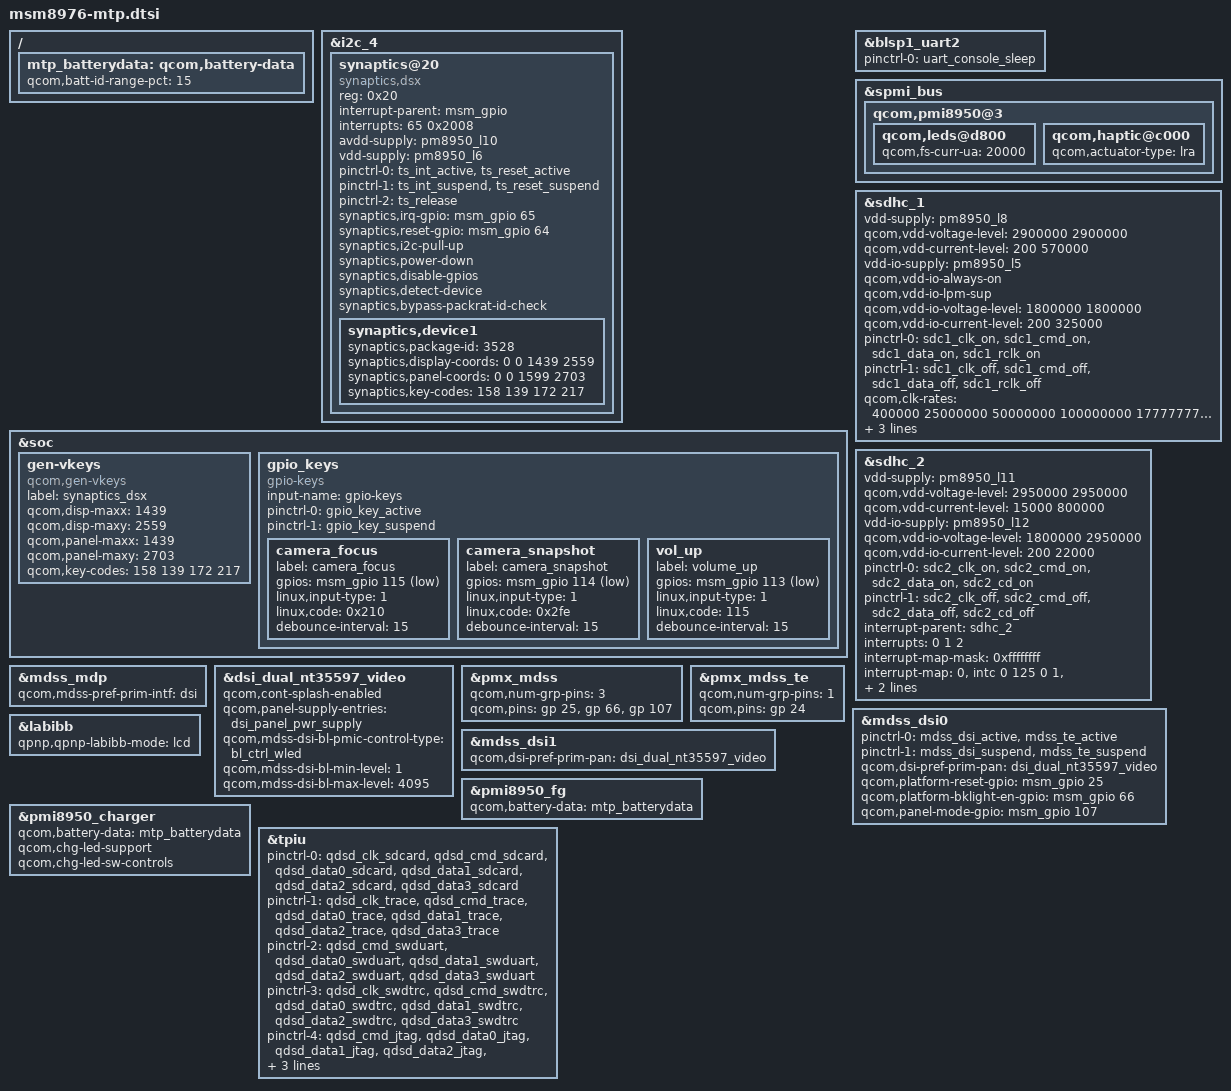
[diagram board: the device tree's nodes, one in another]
/*
 * Copyright (c) 2015, The Linux Foundation. All rights reserved.
 *
 * This program is free software; you can redistribute it and/or modify
 * it under the terms of the GNU General Public License version 2 and
 * only version 2 as published by the Free Software Foundation.
 *
 * This program is distributed in the hope that it will be useful,
 * but WITHOUT ANY WARRANTY; without even the implied warranty of
 * MERCHANTABILITY or FITNESS FOR A PARTICULAR PURPOSE.  See the
 * GNU General Public License for more details.
 */

#include "msm8976.dtsi"
#include "msm8976-pinctrl.dtsi"
#include "msm8976-camera-sensor-mtp.dtsi"

&i2c_4 { /* BLSP1 QUP4 */
	synaptics@20 {
		compatible = "synaptics,dsx";
		reg = <0x20>;
		interrupt-parent = <&msm_gpio>;
		interrupts = <65 0x2008>;
		avdd-supply = <&pm8950_l10>;
		vdd-supply = <&pm8950_l6>;
		/* pins used by touchscreen */
		pinctrl-names = "pmx_ts_active","pmx_ts_suspend","pmx_ts_release";
		pinctrl-0 = <&ts_int_active &ts_reset_active>;
		pinctrl-1 = <&ts_int_suspend &ts_reset_suspend>;
		pinctrl-2 = <&ts_release>;
		synaptics,irq-gpio = <&msm_gpio 65 0x2008>;
		synaptics,reset-gpio = <&msm_gpio 64 0x0>;
		synaptics,i2c-pull-up;
		synaptics,power-down;
		synaptics,disable-gpios;
		synaptics,detect-device;
		synaptics,bypass-packrat-id-check;
		synaptics,device1 {
			synaptics,package-id = <3528>;
			synaptics,display-coords = <0 0 1439 2559>;
			synaptics,panel-coords = <0 0 1599 2703>;
			synaptics,key-codes = <158 139 172 217>;
		};
	};
};

&soc {
	gen-vkeys {
		compatible = "qcom,gen-vkeys";
		label = "synaptics_dsx";
		qcom,disp-maxx = <1439>;
		qcom,disp-maxy = <2559>;
		qcom,panel-maxx = <1439>;
		qcom,panel-maxy = <2703>;
		qcom,key-codes = <158 139 172 217>;
	};

	gpio_keys {
		compatible = "gpio-keys";
		input-name = "gpio-keys";
		pinctrl-names = "tlmm_gpio_key_active","tlmm_gpio_key_suspend";
		pinctrl-0 = <&gpio_key_active>;
		pinctrl-1 = <&gpio_key_suspend>;

		camera_focus {
			label = "camera_focus";
			gpios = <&msm_gpio 115 0x1>;
			linux,input-type = <1>;
			linux,code = <0x210>;
			debounce-interval = <15>;
		};

		camera_snapshot {
			label = "camera_snapshot";
			gpios = <&msm_gpio 114 0x1>;
			linux,input-type = <1>;
			linux,code = <0x2fe>;
			debounce-interval = <15>;
		};

		vol_up {
			label = "volume_up";
			gpios = <&msm_gpio 113 0x1>;
			linux,input-type = <1>;
			linux,code = <115>;
			debounce-interval = <15>;
		};
	};
};

&blsp1_uart2 {
	status = "ok";
	pinctrl-names = "default";
	pinctrl-0 = <&uart_console_sleep>;
};


&spmi_bus {
	qcom,pmi8950@3 {
		qcom,leds@d800 {
			qcom,fs-curr-ua = <20000>;
		};

		qcom,haptic@c000 {
			qcom,actuator-type = "lra";
		};
	};
};

&sdhc_1 {
	vdd-supply = <&pm8950_l8>;
	qcom,vdd-voltage-level = <2900000 2900000>;
	qcom,vdd-current-level = <200 570000>;

	vdd-io-supply = <&pm8950_l5>;
	qcom,vdd-io-always-on;
	qcom,vdd-io-lpm-sup;
	qcom,vdd-io-voltage-level = <1800000 1800000>;
	qcom,vdd-io-current-level = <200 325000>;

	pinctrl-names = "active", "sleep";
	pinctrl-0 = <&sdc1_clk_on &sdc1_cmd_on &sdc1_data_on &sdc1_rclk_on>;
	pinctrl-1 = <&sdc1_clk_off &sdc1_cmd_off &sdc1_data_off &sdc1_rclk_off>;

	qcom,clk-rates = <400000 25000000 50000000 100000000 177777778 400000000>;
	qcom,bus-speed-mode = "HS400_1p8v", "HS200_1p8v", "DDR_1p8v";

	qcom,nonremovable;

	status = "ok";
};

&sdhc_2 {
	vdd-supply = <&pm8950_l11>;
	qcom,vdd-voltage-level = <2950000 2950000>;
	qcom,vdd-current-level = <15000 800000>;

	vdd-io-supply = <&pm8950_l12>;
	qcom,vdd-io-voltage-level = <1800000 2950000>;
	qcom,vdd-io-current-level = <200 22000>;

	pinctrl-names = "active", "sleep";
	pinctrl-0 = <&sdc2_clk_on &sdc2_cmd_on &sdc2_data_on &sdc2_cd_on>;
	pinctrl-1 = <&sdc2_clk_off &sdc2_cmd_off &sdc2_data_off &sdc2_cd_off>;

	#address-cells = <0>;
	interrupt-parent = <&sdhc_2>;
	interrupts = <0 1 2>;
	#interrupt-cells = <1>;
	interrupt-map-mask = <0xffffffff>;
	interrupt-map = <0 &intc 0 125 0
			1 &intc 0 221 0
			2 &msm_gpio 100 0>;
	interrupt-names = "hc_irq", "pwr_irq", "status_irq";
	cd-gpios = <&msm_gpio 100 0x1>;

	status = "ok";
};

&mdss_mdp {
	qcom,mdss-pref-prim-intf = "dsi";
};

&dsi_dual_nt35597_video {
	qcom,cont-splash-enabled;
	qcom,panel-supply-entries = <&dsi_panel_pwr_supply>;
	qcom,mdss-dsi-bl-pmic-control-type = "bl_ctrl_wled";
	qcom,mdss-dsi-bl-min-level = <1>;
	qcom,mdss-dsi-bl-max-level = <4095>;
};

&pmx_mdss {
	qcom,num-grp-pins = <3>;
	qcom,pins = <&gp 25>, <&gp 66>, <&gp 107>;
};

&pmx_mdss_te {
	qcom,num-grp-pins = <1>;
	qcom,pins = <&gp 24>;
};

&mdss_dsi0 {
	pinctrl-names = "mdss_default", "mdss_sleep";
	pinctrl-0 = <&mdss_dsi_active &mdss_te_active>;
	pinctrl-1 = <&mdss_dsi_suspend &mdss_te_suspend>;
	qcom,dsi-pref-prim-pan = <&dsi_dual_nt35597_video>;

	qcom,platform-reset-gpio = <&msm_gpio 25 0>;
	qcom,platform-bklight-en-gpio = <&msm_gpio 66 0>;
	qcom,panel-mode-gpio = <&msm_gpio 107 0>;
};

&mdss_dsi1 {
	qcom,dsi-pref-prim-pan = <&dsi_dual_nt35597_video>;
};

&labibb {
	status = "ok";
	qpnp,qpnp-labibb-mode = "lcd";
};

/{
	mtp_batterydata: qcom,battery-data {
		qcom,batt-id-range-pct = <15>;
		#include "batterydata-itech-3000mah-4200mv.dtsi"
		#include "batterydata-itech-3000mah.dtsi"
	};
};

&pmi8950_fg {
	qcom,battery-data = <&mtp_batterydata>;
};

&pmi8950_charger {
	qcom,battery-data = <&mtp_batterydata>;
	qcom,chg-led-support;
	qcom,chg-led-sw-controls;
};

/* CoreSight */
&tpiu {
	pinctrl-names = "sdcard", "trace", "swduart",
			"swdtrc", "jtag", "spmi";
	/* NIDnT */
	pinctrl-0 = <&qdsd_clk_sdcard &qdsd_cmd_sdcard
		     &qdsd_data0_sdcard &qdsd_data1_sdcard
		     &qdsd_data2_sdcard &qdsd_data3_sdcard>;
	pinctrl-1 = <&qdsd_clk_trace &qdsd_cmd_trace
		     &qdsd_data0_trace &qdsd_data1_trace
		     &qdsd_data2_trace &qdsd_data3_trace>;
	pinctrl-2 = <&qdsd_cmd_swduart &qdsd_data0_swduart
		     &qdsd_data1_swduart &qdsd_data2_swduart
		     &qdsd_data3_swduart>;
	pinctrl-3 = <&qdsd_clk_swdtrc &qdsd_cmd_swdtrc
		     &qdsd_data0_swdtrc &qdsd_data1_swdtrc
		     &qdsd_data2_swdtrc &qdsd_data3_swdtrc>;
	pinctrl-4 = <&qdsd_cmd_jtag &qdsd_data0_jtag
		     &qdsd_data1_jtag &qdsd_data2_jtag
		     &qdsd_data3_jtag>;
	pinctrl-5 = <&qdsd_clk_spmi &qdsd_cmd_spmi
		     &qdsd_data0_spmi &qdsd_data3_spmi>;
};
